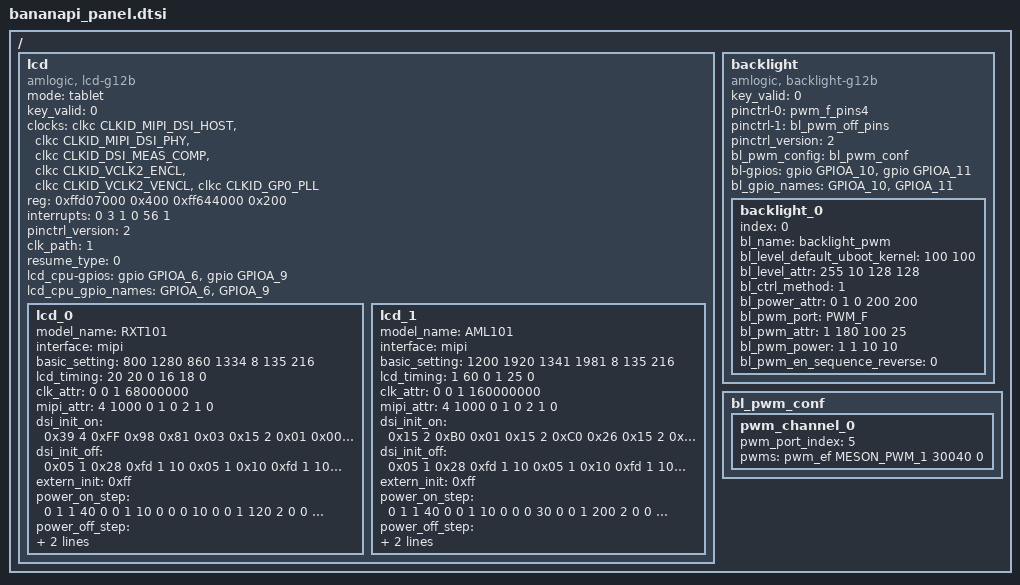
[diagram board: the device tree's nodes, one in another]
/*
 * arch/arm64/boot/dts/amlogic/bananapi_panel.dtsi
 *
 * Copyright (C) 2016 Amlogic, Inc. All rights reserved.
 *
 * This program is free software; you can redistribute it and/or modify
 * it under the terms of the GNU General Public License as published by
 * the Free Software Foundation; either version 2 of the License, or
 * (at your option) any later version.
 *
 * This program is distributed in the hope that it will be useful, but WITHOUT
 * ANY WARRANTY; without even the implied warranty of MERCHANTABILITY or
 * FITNESS FOR A PARTICULAR PURPOSE.  See the GNU General Public License for
 * more details.
 *
 */

/ {
	lcd{
		compatible = "amlogic, lcd-g12b";
		mode = "tablet";
		status = "okay";
		key_valid = <0>;
		clocks = <&clkc CLKID_MIPI_DSI_HOST
			&clkc CLKID_MIPI_DSI_PHY
			&clkc CLKID_DSI_MEAS_COMP
			&clkc CLKID_VCLK2_ENCL
			&clkc CLKID_VCLK2_VENCL
			&clkc CLKID_GP0_PLL>;
		clock-names = "dsi_host_gate",
			"dsi_phy_gate",
			"dsi_meas",
			"encl_top_gate",
			"encl_int_gate",
			"gp0_pll";
		reg = <0xffd07000 0x400    /* dsi_host */
			0xff644000 0x200>; /* dsi_phy */
		interrupts = <0 3 1
			0 56 1>;
		interrupt-names = "vsync","vsync2";
		pinctrl_version = <2>; /* for uboot */
		clk_path = <1>; /* default gp0 pll */
		resume_type = <0>; /* 0:directly resume(dual display preferred),
				    * 1:workqueue resume(default)
				    */

		/* power type:
		 *    (0=cpu_gpio, 1=pmu_gpio, 2=signal,3=extern, 0xff=ending)
		 * power index:
		 *    (point gpios_index, or extern_index,0xff=invalid)
		 * power value:(0=output low, 1=output high, 2=input)
		 * power delay:(unit in ms)
		 */
		lcd_cpu-gpios = <&gpio GPIOA_6 GPIO_ACTIVE_HIGH
				&gpio GPIOA_9 GPIO_ACTIVE_HIGH>;
		lcd_cpu_gpio_names = "GPIOA_6","GPIOA_9";

		lcd_0{
			model_name = "RXT101";
			interface = "mipi";
			basic_setting = <800 1280 /*h_active, v_active*/
				860 1334 /*h_period, v_period*/
				8 /*lcd_bits*/
				135 216>; /*screen_widht, screen_height*/
			lcd_timing = <20 20 0 /*hs_width, hs_bp, hs_pol*/
				16 18 0>; /*vs_width, vs_bp, vs_pol*/
			clk_attr = <0 /*fr_adj_type(0=clk, 1=htotal, 2=vtotal)*/
				0 /*clk_ss_level */
				1 /*clk_auto_generate*/
				68000000>; /*pixel_clk(unit in Hz)*/
			mipi_attr = <4 /*lane_num*/
				1000 /*bit_rate_max(MHz)*/
				0 /*factor(*100, default 0 for auto)*/
				1 /*operation_mode_init(0=video, 1=command)*/
				0 /*operation_mode_display(0=video, 1=command)*/
				2 /*
				   *video_mode_type
				   *(0=sync_pulse,1=sync_event,2=burst)
				   */
				1 /*clk_always_hs(0=disable,1=enable)*/
				0>; /*phy_switch(0=auto,1=standard,2=slow)*/

			/* dsi_init: data_type, num, data... */
			dsi_init_on = <
				0x39 4 0xFF 0x98 0x81 0x03
				0x15 2 0x01 0x00
				0x15 2 0x02 0x00
				0x15 2 0x03 0x53
				0x15 2 0x04 0x53
				0x15 2 0x05 0x13
				0x15 2 0x06 0x04
				0x15 2 0x07 0x02
				0x15 2 0x08 0x02
				0x15 2 0x09 0x00
				0x15 2 0x0a 0x00
				0x15 2 0x0b 0x00
				0x15 2 0x0c 0x00
				0x15 2 0x0d 0x00
				0x15 2 0x0e 0x00
				0x15 2 0x0f 0x00
				0x15 2 0x10 0x00
				0x15 2 0x11 0x00
				0x15 2 0x12 0x00
				0x15 2 0x13 0x00
				0x15 2 0x14 0x00
				0x15 2 0x15 0x00
				0x15 2 0x16 0x00
				0x15 2 0x17 0x00
				0x15 2 0x18 0x00
				0x15 2 0x19 0x00
				0x15 2 0x1a 0x00
				0x15 2 0x1b 0x00
				0x15 2 0x1c 0x00
				0x15 2 0x1d 0x00
				0x15 2 0x1e 0xC0
				0x15 2 0x1f 0x80
				0x15 2 0x20 0x02
				0x15 2 0x21 0x09
				0x15 2 0x22 0x00
				0x15 2 0x23 0x00
				0x15 2 0x24 0x00
				0x15 2 0x25 0x00
				0x15 2 0x26 0x00
				0x15 2 0x27 0x00
				0x15 2 0x28 0x55
				0x15 2 0x29 0x03
				0x15 2 0x2a 0x00
				0x15 2 0x2b 0x00
				0x15 2 0x2c 0x00
				0x15 2 0x2d 0x00
				0x15 2 0x2e 0x00
				0x15 2 0x2f 0x00
				0x15 2 0x30 0x00
				0x15 2 0x31 0x00
				0x15 2 0x32 0x00
				0x15 2 0x33 0x00
				0x15 2 0x34 0x00
				0x15 2 0x35 0x00
				0x15 2 0x36 0x00
				0x15 2 0x37 0x00
				0x15 2 0x38 0x3c
				0x15 2 0x39 0x00
				0x15 2 0x3a 0x00
				0x15 2 0x3b 0x00
				0x15 2 0x3c 0x00
				0x15 2 0x3d 0x00
				0x15 2 0x3e 0x00
				0x15 2 0x3f 0x00
				0x15 2 0x40 0x00
				0x15 2 0x41 0x00
				0x15 2 0x42 0x00
				0x15 2 0x43 0x00
				0x15 2 0x44 0x00
				0x15 2 0x50 0x01
				0x15 2 0x51 0x23
				0x15 2 0x52 0x45
				0x15 2 0x53 0x67
				0x15 2 0x54 0x89
				0x15 2 0x55 0xab
				0x15 2 0x56 0x01
				0x15 2 0x57 0x23
				0x15 2 0x58 0x45
				0x15 2 0x59 0x67
				0x15 2 0x5a 0x89
				0x15 2 0x5b 0xab
				0x15 2 0x5c 0xcd
				0x15 2 0x5d 0xef
				0x15 2 0x5e 0x01
				0x15 2 0x5f 0x0A
				0x15 2 0x60 0x02
				0x15 2 0x61 0x02
				0x15 2 0x62 0x08
				0x15 2 0x63 0x15
				0x15 2 0x64 0x14
				0x15 2 0x65 0x02
				0x15 2 0x66 0x11
				0x15 2 0x67 0x10
				0x15 2 0x68 0x02
				0x15 2 0x69 0x0F
				0x15 2 0x6a 0x0E
				0x15 2 0x6b 0x02
				0x15 2 0x6c 0x0D
				0x15 2 0x6d 0x0C
				0x15 2 0x6e 0x06
				0x15 2 0x6f 0x02
				0x15 2 0x70 0x02
				0x15 2 0x71 0x02
				0x15 2 0x72 0x02
				0x15 2 0x73 0x02
				0x15 2 0x74 0x02
				0x15 2 0x75 0x0A
				0x15 2 0x76 0x02
				0x15 2 0x77 0x02
				0x15 2 0x78 0x06
				0x15 2 0x79 0x15
				0x15 2 0x7a 0x14
				0x15 2 0x7b 0x02
				0x15 2 0x7c 0x10
				0x15 2 0x7d 0x11
				0x15 2 0x7e 0x02
				0x15 2 0x7f 0x0C
				0x15 2 0x80 0x0D
				0x15 2 0x81 0x02
				0x15 2 0x82 0x0E
				0x15 2 0x83 0x0F
				0x15 2 0x84 0x08
				0x15 2 0x85 0x02
				0x15 2 0x86 0x02
				0x15 2 0x87 0x02
				0x15 2 0x88 0x02
				0x15 2 0x89 0x02
				0x15 2 0x8a 0x02
				0x39 4 0xFF 0x98 0x81 0x04
				0x15 2 0x6C 0x15
				0x15 2 0x6E 0x30
				0x15 2 0x6F 0x55
				0x15 2 0x3A 0x24
				0x15 2 0x8D 0x1F
				0x15 2 0x87 0xBA
				0x15 2 0x26 0x76
				0x15 2 0xB2 0xD1
				0x15 2 0xB5 0x07
				0x15 2 0x35 0x1F
				0x15 2 0x31 0x75
				0x15 2 0x3B 0x98
				0x15 2 0x38 0x01
				0x15 2 0x39 0x00
				0x15 2 0x88 0x0B
				0x39 4 0xFF 0x98 0x81 0x01
				0x15 2 0x22 0x0A
				0x15 2 0x31 0x09
				0x15 2 0x35 0x07
				0x15 2 0x53 0x48
				0x15 2 0x40 0x33
				0x15 2 0x55 0x88
				0x15 2 0x50 0x95
				0x15 2 0x51 0x95
				0x15 2 0x60 0x30
				0x15 2 0x34 0x01
				0x15 2 0xA0 0x0F
				0x15 2 0xA1 0x17
				0x15 2 0xA2 0x22
				0x15 2 0xA3 0x19
				0x15 2 0xA4 0x15
				0x15 2 0xA5 0x28
				0x15 2 0xA6 0x1C
				0x15 2 0xA7 0x1C
				0x15 2 0xA8 0x78
				0x15 2 0xA9 0x1C
				0x15 2 0xAA 0x28
				0x15 2 0xAB 0x69
				0x15 2 0xAC 0x1A
				0x15 2 0xAD 0x19
				0x15 2 0xAE 0x4B
				0x15 2 0xAF 0x22
				0x15 2 0xB0 0x2A
				0x15 2 0xB1 0x4B
				0x15 2 0xB2 0x6B
				0x15 2 0xB3 0x3F
				0x15 2 0xC0 0x01
				0x15 2 0xC1 0x17
				0x15 2 0xC2 0x22
				0x15 2 0xC3 0x19
				0x15 2 0xC4 0x15
				0x15 2 0xC5 0x28
				0x15 2 0xC6 0x1C
				0x15 2 0xC7 0x1D
				0x15 2 0xC8 0x78
				0x15 2 0xC9 0x1C
				0x15 2 0xCA 0x28
				0x15 2 0xCB 0x69
				0x15 2 0xCC 0x1A
				0x15 2 0xCD 0x19
				0x15 2 0xCE 0x4B
				0x15 2 0xCF 0x22
				0x15 2 0xD0 0x2A
				0x15 2 0xD1 0x4B
				0x15 2 0xD2 0x6B
				0x15 2 0xD3 0x3F
				0x39 4 0xFF 0x98 0x81 0x00
				0x15 2 0x35 0x00
				0x05 1 0x11
				0xfd 1 120	/*delay 120ms*/
				0x05 1 0x29
				0xfd 1 120	/*delay 120ms*/
				0x39 4 0xFF 0x98 0x81 0x00
				0xff 0>;    /*ending*/
			dsi_init_off = <
				0x05 1 0x28
				0xfd 1 10   /*delay 10ms*/
				0x05 1 0x10
				0xfd 1 10   /*delay 10ms*/
				0xff 0>;    /*ending*/
			extern_init = <0xff>; /*0xff for invalid*/

			/* power step: type, index, value, delay(ms) */
			power_on_step = <
				0 1 1 40
				0 0 1 10
				0 0 0 10
				0 0 1 120
				2 0 0 0
				0xff 0 0 0>; /*ending*/
			power_off_step = <
				2 0 0 50
				0 0 0 10
				0 1 0 100
				0xff 0 0 0>; /*ending*/
			backlight_index = <0>;
		};

		lcd_1{
			model_name = "AML101";
			interface = "mipi";
			basic_setting = <1200 1920 /*h_active, v_active*/
				1341 1981 /*h_period, v_period*/
				8 /*lcd_bits*/
				135 216>; /*screen_widht, screen_height*/
			lcd_timing = <1 60 0 /*hs_width, hs_bp, hs_pol*/
				1 25 0>; /*vs_width, vs_bp, vs_pol*/
			clk_attr = <0 /*fr_adj_type(0=clk, 1=htotal, 2=vtotal)*/
				0 /*clk_ss_level */
				1 /*clk_auto_generate*/
				160000000>; /*pixel_clk(unit in Hz)*/
			mipi_attr = <4 /*lane_num*/
				1000 /*bit_rate_max(MHz)*/
				0 /*factor(*100, default 0 for auto)*/
				1 /*operation_mode_init(0=video, 1=command)*/
				0 /*operation_mode_display(0=video, 1=command)*/
				2 /*
				   *video_mode_type
				   *(0=sync_pulse,1=sync_event,2=burst)
				   */
				1 /*clk_always_hs(0=disable,1=enable)*/
				0>; /*phy_switch(0=auto,1=standard,2=slow)*/

			/* dsi_init: data_type, num, data... */
			dsi_init_on = <
				0x15 2 0xB0 0x01
				0x15 2 0xC0 0x26
				0x15 2 0xC1 0x10
				0x15 2 0xC2 0x0E
				0x15 2 0xC3 0x00
				0x15 2 0xC4 0x00
				0x15 2 0xC5 0x23
				0x15 2 0xC6 0x11
				0x15 2 0xC7 0x22
				0x15 2 0xC8 0x20
				0x15 2 0xC9 0x1E
				0x15 2 0xCA 0x1C
				0x15 2 0xCB 0x0C
				0x15 2 0xCC 0x0A
				0x15 2 0xCD 0x08
				0x15 2 0xCE 0x06
				0x15 2 0xCF 0x18
				0x15 2 0xD0 0x02
				0x15 2 0xD1 0x00
				0x15 2 0xD2 0x00
				0x15 2 0xD3 0x00
				0x15 2 0xD4 0x26
				0x15 2 0xD5 0x0F
				0x15 2 0xD6 0x0D
				0x15 2 0xD7 0x00
				0x15 2 0xD8 0x00
				0x15 2 0xD9 0x23
				0x15 2 0xDA 0x11
				0x15 2 0xDB 0x21
				0x15 2 0xDC 0x1F
				0x15 2 0xDD 0x1D
				0x15 2 0xDE 0x1B
				0x15 2 0xDF 0x0B
				0x15 2 0xE0 0x09
				0x15 2 0xE1 0x07
				0x15 2 0xE2 0x05
				0x15 2 0xE3 0x17
				0x15 2 0xE4 0x01
				0x15 2 0xE5 0x00
				0x15 2 0xE6 0x00
				0x15 2 0xE7 0x00
				0x15 2 0xB0 0x03
				0x15 2 0xBE 0x04
				0x15 2 0xB9 0x40
				0x15 2 0xCC 0x88
				0x15 2 0xC8 0x0C
				0x15 2 0xC9 0x07
				0x15 2 0xCD 0x01
				0x15 2 0xCA 0x40
				0x15 2 0xCE 0x1A
				0x15 2 0xCF 0x60
				0x15 2 0xD2 0x08
				0x15 2 0xD3 0x08
				0x15 2 0xDB 0x01
				0x15 2 0xD9 0x06
				0x15 2 0xD4 0x00
				0x15 2 0xD5 0x01
				0x15 2 0xD6 0x04
				0x15 2 0xD7 0x03
				0x15 2 0xC2 0x00
				0x15 2 0xC3 0x0E
				0x15 2 0xC4 0x00
				0x15 2 0xC5 0x0E
				0x15 2 0xDD 0x00
				0x15 2 0xDE 0x0E
				0x15 2 0xE6 0x00
				0x15 2 0xE7 0x0E
				0x15 2 0xC2 0x00
				0x15 2 0xC3 0x0E
				0x15 2 0xC4 0x00
				0x15 2 0xC5 0x0E
				0x15 2 0xDD 0x00
				0x15 2 0xDE 0x0E
				0x15 2 0xE6 0x00
				0x15 2 0xE7 0x0E
				0x15 2 0xB0 0x06
				0x15 2 0xC0 0xA5
				0x15 2 0xD5 0x1C
				0x15 2 0xC0 0x00
				0x15 2 0xB0 0x00
				0x15 2 0xBD 0x30

				0x15 2 0xF9 0x5C
				0x15 2 0xC2 0x14
				0x15 2 0xC4 0x14
				0x15 2 0xBF 0x15
				0x15 2 0xC0 0x0C

				0x15 2 0xB0 0x00
				0x15 2 0xB1 0x79
				0x15 2 0xBA 0x8F

				0x05 1 0x11
				0xfd 1 120 /*delay 120ms*/
				0x05 1 0x29
				0xfd 1 120 /*delay 120ms*/
				0xff 0>; /*ending*/

			dsi_init_off = <
				0x05 1 0x28
				0xfd 1 10   /*delay 10ms*/
				0x05 1 0x10
				0xfd 1 10   /*delay 10ms*/
				0xff 0>;    /*ending*/
			extern_init = <0xff>; /*0xff for invalid*/

			/* power step: type, index, value, delay(ms) */
			power_on_step = <
				0 1 1 40
				0 0 1 10
				0 0 0 30
				0 0 1 200
				2 0 0 0
				0xff 0 0 0>; /*ending*/
			power_off_step = <
				2 0 0 50
				0 0 0 10
				0 1 0 100
				0xff 0 0 0>; /*ending*/
			backlight_index = <0>;
		};
	};

	backlight{
		compatible = "amlogic, backlight-g12b";
		status = "okay";
		key_valid = <0>;
		pinctrl-names = "pwm_on","pwm_off";
		pinctrl-0 = <&pwm_f_pins4>;
		pinctrl-1 = <&bl_pwm_off_pins>;
		pinctrl_version = <2>; /* for uboot */
		bl_pwm_config = <&bl_pwm_conf>;
		bl-gpios = <&gpio GPIOA_10 GPIO_ACTIVE_HIGH
			&gpio GPIOA_11 GPIO_ACTIVE_HIGH>;
		bl_gpio_names = "GPIOA_10","GPIOA_11";

		/* pwm port: PWM_A, PWM_B, PWM_C, PWM_D, PWM_E, PWM_F, PWM_VS*/
		/* power index:(point gpios_index, 0xff=invalid)
		 * power value:(0=output low, 1=output high, 2=input)
		 * power delay:(unit in ms)
		 */

		backlight_0{
			index = <0>;
			bl_name = "backlight_pwm";
			bl_level_default_uboot_kernel = <100 100>;
			bl_level_attr = <255 10 /*max, min*/
				128 128>; /*mid, mid_mapping*/
			bl_ctrl_method = <1>; /* 1=pwm, 2=pwm_combo, 4=extern */
			bl_power_attr = <0 /*en_gpio_index*/
				1 0 /*on_value, off_value*/
				200 200>; /*on_delay(ms), off_delay(ms)*/
			bl_pwm_port = "PWM_F";
			bl_pwm_attr = <1 /*pwm_method(polarity)*/
				180 /*pwm_freq(pwm:Hz, pwm_vs:multiple of vs)*/
				100 25>; /*duty_max(%), duty_min(%)*/
			bl_pwm_power = <1 1 /*pwm_gpio_index, pwm_gpio_off*/
				10 10>; /*pwm_on_delay(ms), pwm_off_delay(ms)*/
			bl_pwm_en_sequence_reverse = <0>; /* 1 for reverse */
		};
	};
	bl_pwm_conf:bl_pwm_conf{
		pwm_channel_0 {
			pwm_port_index = <5>;
			pwms = <&pwm_ef MESON_PWM_1 30040 0>;
		};
	};
};/* end of panel */

